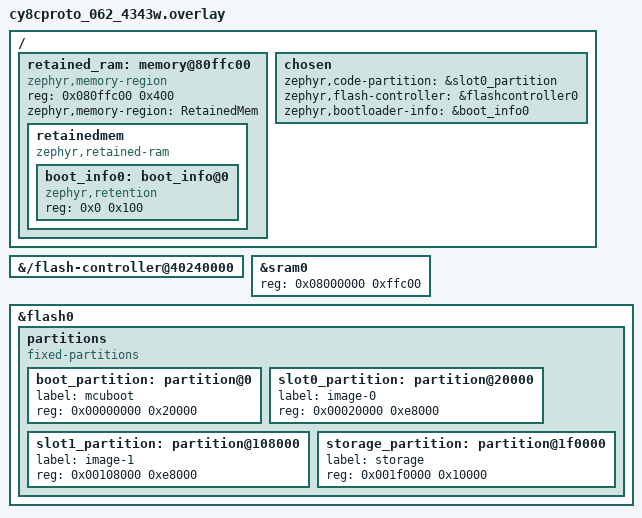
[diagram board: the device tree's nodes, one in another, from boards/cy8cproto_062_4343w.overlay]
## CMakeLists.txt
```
cmake_minimum_required(VERSION 3.20.0)

if (EXISTS "${CMAKE_CURRENT_SOURCE_DIR}/credentials.conf")
    list(APPEND EXTRA_CONF_FILE "${CMAKE_CURRENT_SOURCE_DIR}/credentials.conf")
endif()

find_package(Zephyr REQUIRED HINTS $ENV{ZEPHYR_BASE})
project(ota)

# This sample enables automatic main-firmware handling and requires MCUboot via sysbuild.
test_sysbuild()

add_subdirectory(../net-common ${CMAKE_CURRENT_BINARY_DIR}/net-common)

target_sources(app PRIVATE
    src/main.c
)

# PSoC6 RAM-load under MCUboot:
# - Omit the app CM0+ ROM blob so vectors follow ROM_START_OFFSET.
# - ROM_START_OFFSET is 0x2000 so load_addr+header matches the CM4 VTOR.
# - Re-sign with max-align=512 / erase-value 0 (imgtool CLI cannot).
if(BOARD MATCHES "^cy8cproto_062_4343w")
	set(snippet_base ${CMAKE_BINARY_DIR}/zephyr/include/generated)
	# Keep all ROM_START includes except the CM0+ sleep image reservation.
	file(WRITE ${snippet_base}/snippets-rom-start.ld
		"/* Sort key: \"!\" */#include \"../arch/common/rom_start_address.ld\"\n"
		"/* Sort key: \"$\" */#include \"../arch/common/fill_with_zeros.ld\"\n"
		"/* Sort key: \"0x0\" */#include \"../arch/common/rom_start_offset.ld\"\n"
		"/* Spotflow OTA: skip soc CM0+ blob; pad so vectors are at load+0x2000. */\n"
		"__cy_m0p_code_start = . ;\n"
		"__cy_m0p_code_end = . ;\n"
		". += 0x1e00;\n"
		". = ALIGN(4);\n"
		"/* Sort key: \"0x0vectors\" */#include \"../arch/arm/core/vector_table.ld\"\n"
		"/* Sort key: \"0x0vectors\" */#include \"zephyr/linker/irq-vector-table-section.ld\"\n"
		"/* Sort key: \"0x1vectors\" */#include \"../arch/arm/core/cortex_m/vector_table_pad.ld\"\n"
	)
	file(WRITE ${snippet_base}/snippets-ram-sections.ld
		"/* Spotflow OTA: no CM0+ RAM reservation under MCUboot RAM-load. */\n"
		"SECTION_PROLOGUE(.ram_m0p_image,(NOLOAD),)\n"
		"{\n"
		"} GROUP_DATA_LINK_IN(RAMABLE_REGION, RAMABLE_REGION)\n"
		"/* Sort key: \"default\" */#include \"../arch/common/ramfunc.ld\"\n"
	)

	set(psoc6_resign ${CMAKE_CURRENT_SOURCE_DIR}/scripts/psoc6_resign.py)
	set(psoc6_key ${ZEPHYR_MCUBOOT_MODULE_DIR}/root-rsa-2048.pem)
	if(NOT EXISTS "${psoc6_key}")
		set(psoc6_key ${ZEPHYR_BASE}/../bootloader/mcuboot/root-rsa-2048.pem)
	endif()
	# Run after the stock imgtool sign (also a zephyr_final POST_BUILD).
	add_custom_command(TARGET zephyr_final POST_BUILD
		COMMAND ${PYTHON_EXECUTABLE} ${psoc6_resign}
			--in-bin ${CMAKE_BINARY_DIR}/zephyr/zephyr.bin
			--out-bin ${CMAKE_BINARY_DIR}/zephyr/zephyr.signed.bin
			--out-hex ${CMAKE_BINARY_DIR}/zephyr/zephyr.signed.hex
			--key ${psoc6_key}
			--header-size 0x2000
		COMMAND ${CMAKE_COMMAND} -E copy
			${CMAKE_BINARY_DIR}/zephyr/zephyr.signed.bin
			${CMAKE_BINARY_DIR}/zephyr/zephyr.signed.confirmed.bin
		COMMAND ${CMAKE_COMMAND} -E copy
			${CMAKE_BINARY_DIR}/zephyr/zephyr.signed.hex
			${CMAKE_BINARY_DIR}/zephyr/zephyr.signed.confirmed.hex
		COMMENT "Re-signing PSoC6 image for RAM_LOAD_REVERT (max-align 512)"
	)
endif()
```

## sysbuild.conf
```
# The MCUboot bootloader must be enabled for automatic handling of main firmware OTA updates
SB_CONFIG_BOOTLOADER_MCUBOOT=y
```

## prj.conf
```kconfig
# Boards that support both Wi-Fi and Ethernet use Wi-Fi by default.
# If you want to use Ethernet instead, please use the following option:
# CONFIG_SPOTFLOW_USE_ETH=y

# Enable Spotflow and OTA updates
CONFIG_SPOTFLOW=y
CONFIG_SPOTFLOW_OTA=y

# Let the SDK handle main firmware download, MCUboot test upgrade, and reboot.
CONFIG_SPOTFLOW_OTA_AUTO_HANDLE_MAIN_FIRMWARE=y

# Enable Spotflow reboot and heartbeat metrics, disable others
CONFIG_SPOTFLOW_METRICS=y
CONFIG_SPOTFLOW_METRICS_HEARTBEAT=y
CONFIG_SPOTFLOW_METRICS_SYSTEM=y
CONFIG_SPOTFLOW_METRICS_SYSTEM_HEAP=n
CONFIG_SPOTFLOW_METRICS_SYSTEM_NETWORK=n
CONFIG_SPOTFLOW_METRICS_SYSTEM_CPU=n
CONFIG_SPOTFLOW_METRICS_SYSTEM_CONNECTION=n
CONFIG_SPOTFLOW_METRICS_SYSTEM_RESET_CAUSE=y
CONFIG_SPOTFLOW_METRICS_SYSTEM_STACK=n

# Enable logging
CONFIG_LOG=y

# Show function names in the logs
CONFIG_LOG_FUNC_NAME_PREFIX_INF=y
CONFIG_LOG_FUNC_NAME_PREFIX_WRN=y
CONFIG_LOG_FUNC_NAME_PREFIX_ERR=y

# Log details of OTA updates for debugging
CONFIG_SPOTFLOW_OTA_LOG_LEVEL=4

# Satisfy networking dependencies of Spotflow
CONFIG_NETWORKING=y
CONFIG_NET_MGMT=y
CONFIG_NET_MGMT_EVENT=y
CONFIG_NET_MGMT_EVENT_INFO=y
CONFIG_NET_CONFIG_AUTO_INIT=n
CONFIG_NET_CONNECTION_MANAGER=y
CONFIG_NET_DHCPV4=y
CONFIG_NET_IPV4=y
CONFIG_NET_IPV6=n
CONFIG_NET_TCP=y
CONFIG_NET_UDP=y

# Enable a persistent settings backend so OTA worker results can be saved and reported.
CONFIG_SETTINGS=y
CONFIG_NVS=y
CONFIG_SETTINGS_NVS=y

# Required by automatic main-firmware handling.
CONFIG_FLASH=y
CONFIG_FLASH_MAP=y
CONFIG_STREAM_FLASH=y

# Increase main stack size for the sample
CONFIG_MAIN_STACK_SIZE=4096

# Ensures that connection is established even on boards without hardware random number generator.
# We recommend removing this option for production use.
CONFIG_MBEDTLS_PSA_CRYPTO_LEGACY_RNG=y
```

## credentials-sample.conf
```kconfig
# Copy this file to credentials.conf and fill in the values
CONFIG_NET_WIFI_SSID=""
CONFIG_NET_WIFI_PASSWORD=""
CONFIG_SPOTFLOW_DEVICE_ID="your-device-id"
CONFIG_SPOTFLOW_INGEST_KEY="your-ingest-key"
```

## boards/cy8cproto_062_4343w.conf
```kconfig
# No hardware random number generator is available on this board by default.
CONFIG_TEST_RANDOM_GENERATOR=y

# The PSoC6 flash driver writes 512-byte rows (erase value 0x00). imgtool's
# CLI cannot emit max-align=512 trailers, so the default signing pass is only a
# placeholder: scripts/psoc6_resign.py rewrites zephyr.signed.{bin,hex} with
# the correct trailer (see CMakeLists.txt). OVERWRITE_ONLY keeps the stock
# imgtool invocation from passing --align 512 (rejected by the CLI).
CONFIG_MCUBOOT_IMGTOOL_OVERWRITE_ONLY=y
CONFIG_MCUBOOT_EXTRA_IMGTOOL_ARGS="--load-addr 0x08000000 --hex-addr 0x10020000"
CONFIG_MCUBOOT_GENERATE_CONFIRMED_IMAGE=y

# ROM_START_OFFSET stays 0x200 under BOOTLOADER_MCUBOOT (not user-settable).
# CMakeLists.txt pads the remaining 0x1E00 so vectors are at 0x08002000 and
# scripts/psoc6_resign.py uses --header-size 0x2000 to match.

# The application needs the active slot from MCUboot so it writes an update to
# the other slot.
CONFIG_RETAINED_MEM=y
CONFIG_RETENTION=y
CONFIG_RETAINED_MEM_ZEPHYR_RAM=y
CONFIG_RETENTION_BOOTLOADER_INFO=y
CONFIG_RETENTION_BOOTLOADER_INFO_TYPE_MCUBOOT=y

# The Armv7-M MPU rounds the approximately 790 KiB RAM-loaded image up to a
# 1 MiB region, leaving no room for runtime data.
CONFIG_ARM_MPU=n

# Preserve enough RAM for the OTA-focused sample by omitting optional metrics.
CONFIG_SPOTFLOW_METRICS=n
CONFIG_SPOTFLOW_METRICS_HEARTBEAT=n
CONFIG_SPOTFLOW_METRICS_SYSTEM=n
CONFIG_SPOTFLOW_METRICS_SYSTEM_RESET_CAUSE=n
```

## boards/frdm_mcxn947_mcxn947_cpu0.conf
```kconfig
# TODO: Copied from RW612, test if needed
CONFIG_NET_BUF_DATA_SIZE=256
```

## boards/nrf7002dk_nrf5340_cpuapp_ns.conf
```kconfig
# This value isn't propagated from Spotflow Kconfig on Nordic boards, so it must be set manually
# at least to 512 (minimal value necessary to validate the MQTT broker certificate)
CONFIG_MBEDTLS_MPI_MAX_SIZE=512

# Spotflow's MQTT/TLS transport still uses the legacy mbedTLS configuration symbols. NCS 3.2.4
# defaults non-secure nRF5340 applications to PSA-only crypto, so explicitly enable the compatibility
# layer until the transport is fully migrated to PSA.
CONFIG_MBEDTLS_LEGACY_CRYPTO_C=y
```

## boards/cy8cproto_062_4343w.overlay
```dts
/*
 * MCUboot flash layout for CY8CPROTO-062-4343W (2 MiB internal flash).
 *
 * The PSoC6 internal flash uses 512-byte rows, so every partition size is a
 * multiple of 512 bytes. RAM load lets both slots contain the same image.
 */

/* MCUboot needs the flash-controller chosen node on this board. */
flashcontroller0: &{/flash-controller@40240000} {};

/ {
	retained_ram: memory@80ffc00 {
		compatible = "zephyr,memory-region", "mmio-sram";
		reg = <0x080ffc00 0x400>;
		ranges = <0x0 0x080ffc00 0x400>;
		zephyr,memory-region = "RetainedMem";
		status = "okay";
		#address-cells = <1>;
		#size-cells = <1>;

		retainedmem {
			compatible = "zephyr,retained-ram";
			status = "okay";
			ranges;
			#address-cells = <1>;
			#size-cells = <1>;

			boot_info0: boot_info@0 {
				compatible = "zephyr,retention";
				status = "okay";
				reg = <0x0 0x100>;
			};
		};
	};

	chosen {
		zephyr,code-partition = &slot0_partition;
		zephyr,flash-controller = &flashcontroller0;
		zephyr,bootloader-info = &boot_info0;
	};
};

/* Keep the retained boot information outside the application RAM region. */
&sram0 {
	reg = <0x08000000 0xffc00>;
};

&flash0 {
	partitions {
		compatible = "fixed-partitions";
		#address-cells = <1>;
		#size-cells = <1>;

		boot_partition: partition@0 {
			label = "mcuboot";
			reg = <0x00000000 0x20000>;
		};

		slot0_partition: partition@20000 {
			label = "image-0";
			reg = <0x00020000 0xe8000>;
		};

		slot1_partition: partition@108000 {
			label = "image-1";
			reg = <0x00108000 0xe8000>;
		};

		storage_partition: partition@1f0000 {
			label = "storage";
			reg = <0x001f0000 0x10000>;
		};
	};
};
```

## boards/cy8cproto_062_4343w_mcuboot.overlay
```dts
/* Application partitions and retained boot information. */
#include "cy8cproto_062_4343w.overlay"

/*
 * Keep MCUboot's data above the application bytes copied from flash. The
 * application reclaims this memory for its runtime data after handoff.
 */
/ {
	mcuboot_sram: memory@80f0000 {
		compatible = "mmio-sram";
		reg = <0x080f0000 0xfc00>;
	};

	chosen {
		zephyr,sram = &mcuboot_sram;
		/* Application overlay selects slot0; MCUboot must stay in boot. */
		zephyr,code-partition = &boot_partition;
	};
};
```

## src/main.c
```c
#include "net.h"

#include <spotflow/ota.h>

#include <zephyr/kernel.h>
#include <zephyr/logging/log.h>

LOG_MODULE_REGISTER(ota_sample, LOG_LEVEL_INF);

static const char* ota_phase_name(enum spotflow_ota_phase phase);
static void confirm_unconfirmed_main_firmware(void);

void spotflow_on_main_firmware_update_progressed(
	const struct spotflow_ota_main_firmware_state* state)
{
	if (state == NULL) {
		return;
	}

	LOG_INF("Main firmware progress: phase=%s paused=%d result=%d",
		ota_phase_name(state->phase), state->is_paused, state->result);
}

enum spotflow_ota_result
spotflow_on_handle_firmware_update(const struct spotflow_firmware_info* info)
{
	if (info == NULL) {
		LOG_ERR("Non-main firmware callback received NULL info");
		return SPOTFLOW_OTA_RESULT_FAILED;
	}

	LOG_INF("Non-main firmware update requested: slug='%s' version=%s", info->slug,
		info->version);

	if (spotflow_is_update_canceled()) {
		LOG_INF("Non-main firmware update canceled before handling");
		return SPOTFLOW_OTA_RESULT_CANCELED;
	}

	/*
	 * Implement delegated firmware updates here. Use info->download_request with
	 * spotflow_download_artifact() to stream the artifact, then return a terminal
	 * spotflow_ota_result. This sample does not handle non-main artifacts.
	 */
	LOG_WRN("Non-main firmware updates are not implemented in this sample");
	return SPOTFLOW_OTA_RESULT_FAILED;
}

void spotflow_on_update_canceled(void)
{
	LOG_INF("OTA update canceled by the cloud");
}

int main(void)
{
	LOG_INF("Starting Spotflow OTA sample");

	confirm_unconfirmed_main_firmware();

	/* Wait for the network device to initialize. */
	k_sleep(K_SECONDS(1));

	spotflow_sample_net_init();

	LOG_INF("Ready to receive OTA updates");

	return 0;
}

static const char* ota_phase_name(enum spotflow_ota_phase phase)
{
	switch (phase) {
	case SPOTFLOW_OTA_PHASE_NOT_RUNNING:
		return "NOT_RUNNING";
	case SPOTFLOW_OTA_PHASE_PENDING_DOWNLOAD:
		return "PENDING_DOWNLOAD";
	case SPOTFLOW_OTA_PHASE_DOWNLOADING:
		return "DOWNLOADING";
	case SPOTFLOW_OTA_PHASE_PENDING_UPGRADE:
		return "PENDING_UPGRADE";
	case SPOTFLOW_OTA_PHASE_PENDING_REBOOT:
		return "PENDING_REBOOT";
	case SPOTFLOW_OTA_PHASE_UNCONFIRMED:
		return "UNCONFIRMED";
	default:
		return "UNKNOWN";
	}
}

static void confirm_unconfirmed_main_firmware(void)
{
	struct spotflow_ota_main_firmware_state fw_state;
	int ret = spotflow_get_main_firmware_update_state(&fw_state);

	if (ret < 0) {
		LOG_ERR("Failed to query main firmware state: %d", ret);
		return;
	}

	if (fw_state.phase != SPOTFLOW_OTA_PHASE_UNCONFIRMED) {
		LOG_INF("Main firmware state: phase=%s result=%d", ota_phase_name(fw_state.phase),
			fw_state.result);
		return;
	}

	LOG_INF("Unconfirmed main firmware detected (phase=%s), confirming via Spotflow OTA",
		ota_phase_name(fw_state.phase));

	ret = spotflow_confirm_main_firmware_image(&fw_state);
	if (ret < 0) {
		LOG_ERR("Failed to confirm main firmware image: %d (phase=%s result=%d)", ret,
			ota_phase_name(fw_state.phase), fw_state.result);
		return;
	}

	LOG_INF("Main firmware confirmed successfully (phase=%s result=%d)",
		ota_phase_name(fw_state.phase), fw_state.result);
}
```
